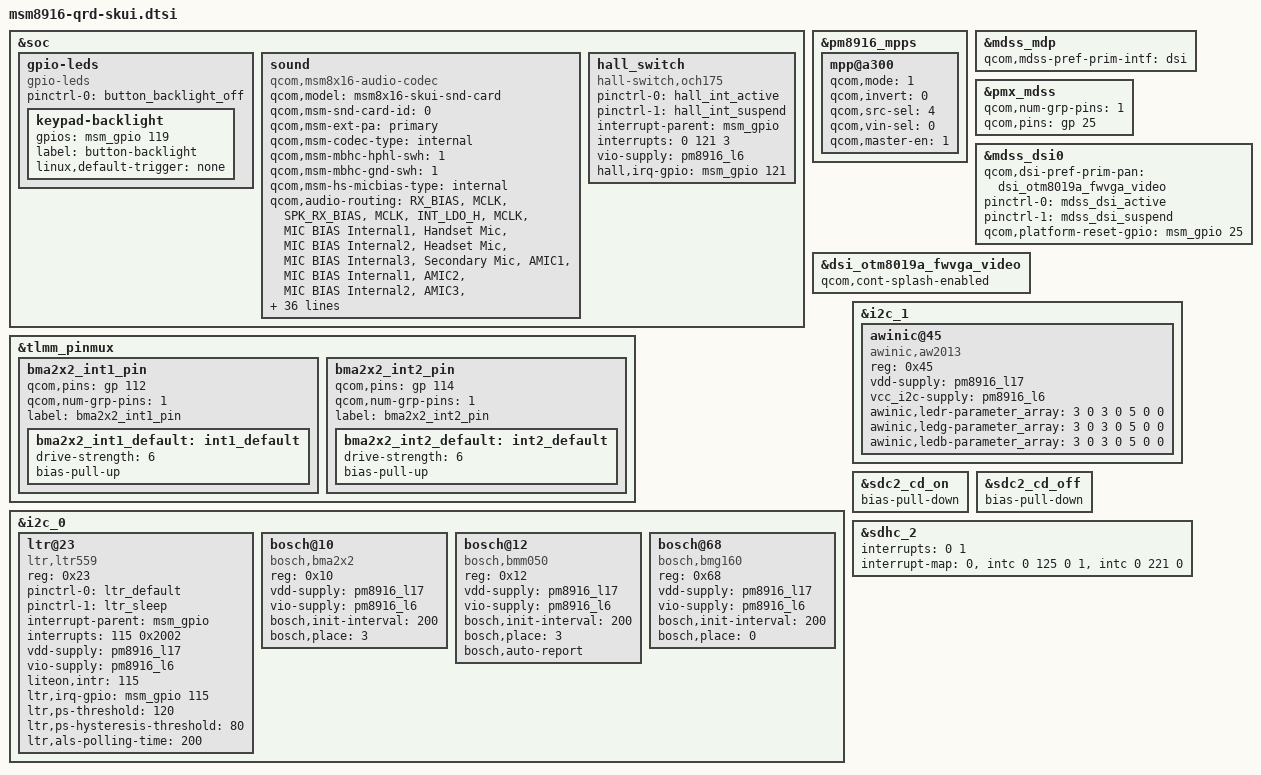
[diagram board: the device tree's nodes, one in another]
/* Copyright (c) 2014, The Linux Foundation. All rights reserved.
 *
 * This program is free software; you can redistribute it and/or modify
 * it under the terms of the GNU General Public License version 2 and
 * only version 2 as published by the Free Software Foundation.
 *
 * This program is distributed in the hope that it will be useful,
 * but WITHOUT ANY WARRANTY; without even the implied warranty of
 * MERCHANTABILITY or FITNESS FOR A PARTICULAR PURPOSE.  See the
 * GNU General Public License for more details.
 */

#include "msm8916-qrd.dtsi"
#include "dsi-panel-otm8019a-fwvga-video.dtsi"
#include "msm8916-camera-sensor-qrd-skui.dtsi"
#include "dsi-panel-dijingILI9881C-720p-video.dtsi"
#include "dsi-panel-booyiOTM1287-720p-video.dtsi"

&soc {
	gpio-leds {
		compatible = "gpio-leds";
		status = "okay";
		pinctrl-names = "default";
		pinctrl-0 = <&button_backlight_off>;

		keypad-backlight {
			gpios = <&msm_gpio 119 0>;
			label = "button-backlight";
			linux,default-trigger = "none";
		};
	};

	sound {
		compatible = "qcom,msm8x16-audio-codec";
		qcom,model = "msm8x16-skui-snd-card";
		qcom,msm-snd-card-id = <0>;
		qcom,msm-ext-pa = "primary";
		qcom,msm-codec-type = "internal";
		qcom,msm-mbhc-hphl-swh = <1>;
		qcom,msm-mbhc-gnd-swh = <1>;
		qcom,msm-hs-micbias-type = "internal";
		qcom,audio-routing =
			"RX_BIAS", "MCLK",
			"SPK_RX_BIAS", "MCLK",
			"INT_LDO_H", "MCLK",
			"MIC BIAS Internal1", "Handset Mic",
			"MIC BIAS Internal2", "Headset Mic",
			"MIC BIAS Internal3", "Secondary Mic",
			"AMIC1", "MIC BIAS Internal1",
			"AMIC2", "MIC BIAS Internal2",
			"AMIC3", "MIC BIAS Internal3";
		pinctrl-names = "cdc_lines_act",
				"cdc_lines_sus";
		pinctrl-0 = <&cdc_pdm_lines_act>;
		pinctrl-1 = <&cdc_pdm_lines_sus>;
		asoc-platform = <&pcm0>, <&pcm1>, <&voip>, <&voice>,
				<&loopback>, <&compress>, <&hostless>,
				<&afe>, <&lsm>, <&routing>, <&lpa>;
		asoc-platform-names = "msm-pcm-dsp.0", "msm-pcm-dsp.1",
				"msm-voip-dsp", "msm-pcm-voice", "msm-pcm-loopback",
				"msm-compress-dsp", "msm-pcm-hostless", "msm-pcm-afe",
				"msm-lsm-client", "msm-pcm-routing", "msm-pcm-lpa";
		asoc-cpu = <&dai_pri_auxpcm>, <&dai_hdmi>,
				<&dai_mi2s0>, <&dai_mi2s1>, <&dai_mi2s2>, <&dai_mi2s3>,
				<&sb_0_rx>, <&sb_0_tx>, <&sb_1_rx>, <&sb_1_tx>,
				<&sb_3_rx>, <&sb_3_tx>, <&sb_4_rx>, <&sb_4_tx>,
				<&bt_sco_rx>, <&bt_sco_tx>, <&int_fm_rx>, <&int_fm_tx>,
				<&afe_pcm_rx>, <&afe_pcm_tx>, <&afe_proxy_rx>, <&afe_proxy_tx>,
				<&incall_record_rx>, <&incall_record_tx>, <&incall_music_rx>,
				<&incall_music_2_rx>;
		asoc-cpu-names = "msm-dai-q6-auxpcm.1", "msm-dai-q6-hdmi.8",
				"msm-dai-q6-mi2s.0", "msm-dai-q6-mi2s.1",
				"msm-dai-q6-mi2s.2", "msm-dai-q6-mi2s.3",
				"msm-dai-q6-dev.16384", "msm-dai-q6-dev.16385",
				"msm-dai-q6-dev.16386", "msm-dai-q6-dev.16387",
				"msm-dai-q6-dev.16390", "msm-dai-q6-dev.16391",
				"msm-dai-q6-dev.16392", "msm-dai-q6-dev.16393",
				"msm-dai-q6-dev.12288", "msm-dai-q6-dev.12289",
				"msm-dai-q6-dev.12292", "msm-dai-q6-dev.12293",
				"msm-dai-q6-dev.224", "msm-dai-q6-dev.225",
				"msm-dai-q6-dev.241", "msm-dai-q6-dev.240",
				"msm-dai-q6-dev.32771", "msm-dai-q6-dev.32772",
				"msm-dai-q6-dev.32773", "msm-dai-q6-dev.32770";
		asoc-codec = <&stub_codec>, <&pm8916_tombak_dig>;
		asoc-codec-names = "msm-stub-codec.1", "tombak_codec";
	};

	//Add hall switch
	hall_switch {
		compatible = "hall-switch,och175";
		pinctrl-names = "hall_active","hall_suspend";
		pinctrl-0 = <&hall_int_active>;
		pinctrl-1 = <&hall_int_suspend>;
		interrupt-parent = <&msm_gpio>;
		interrupts = <0 121 3>;
		vio-supply = <&pm8916_l6>;
		interrupt-names = "hall_irq";
		hall,irq-gpio = <&msm_gpio 121 0x00>;
	};
};

&pm8916_mpps {
	mpp@a300 { /* MPP 4 */
		/* Backlight PWM */
		qcom,mode = <1>;		/* Digital output */
		qcom,invert = <0>;		/* Disable invert */
		qcom,src-sel = <4>;		/* DTEST1 */
		qcom,vin-sel = <0>;		/* VPH_PWR */
		qcom,master-en = <1>;		/* Enable MPP */
	};
};

&mdss_mdp {
	qcom,mdss-pref-prim-intf = "dsi";
};

&pmx_mdss {
	qcom,num-grp-pins = <1>;
	qcom,pins = <&gp 25>;
};

&mdss_dsi0 {
	qcom,dsi-pref-prim-pan = <&dsi_otm8019a_fwvga_video>;
	pinctrl-names = "mdss_default", "mdss_sleep";
	pinctrl-0 = <&mdss_dsi_active>;
	pinctrl-1 = <&mdss_dsi_suspend>;

	qcom,platform-reset-gpio = <&msm_gpio 25 0>;
};

&dsi_otm8019a_fwvga_video {
       qcom,cont-splash-enabled;
};

&tlmm_pinmux {
	bma2x2_int1_pin {
		qcom,pins = <&gp 112>;
		qcom,num-grp-pins = <1>;
		label = "bma2x2_int1_pin";
		bma2x2_int1_default: int1_default {
			  drive-strength = <6>;
			  bias-pull-up;
		};
	};

	bma2x2_int2_pin {
		qcom,pins = <&gp 114>;
		qcom,num-grp-pins = <1>;
		label = "bma2x2_int2_pin";
		bma2x2_int2_default: int2_default {
			  drive-strength = <6>;
			  bias-pull-up;
		};
	};
};

&i2c_0 { /* BLSP1 QUP2 */
	ltr@23 { /* Ambient light and proximity sensor */
		compatible = "ltr,ltr559";
		reg = <0x23>;
		pinctrl-names = "default","sleep";
		pinctrl-0 = <&ltr_default>;
		pinctrl-1 = <&ltr_sleep>;
		interrupt-parent = <&msm_gpio>;
		interrupts = <115 0x2002>;
		vdd-supply = <&pm8916_l17>;
		vio-supply = <&pm8916_l6>;
		liteon,intr = <115>;
		ltr,irq-gpio = <&msm_gpio 115 0x2002>;
		ltr,ps-threshold = <120>;
		ltr,ps-hysteresis-threshold = <80>;
		ltr,als-polling-time = <200>;
	};

	bosch@10 { /* accelerometer sensor */
		compatible = "bosch,bma2x2";
		reg = <0x10>;
		vdd-supply = <&pm8916_l17>;
		vio-supply = <&pm8916_l6>;
		bosch,init-interval = <200>;
		bosch,place = <3>;
	};
	bosch@12 {/* magnetic sensor */
		compatible = "bosch,bmm050";
		reg = <0x12>;
		vdd-supply = <&pm8916_l17>;
		vio-supply = <&pm8916_l6>;
		bosch,init-interval = <200>;
		bosch,place = <3>;
		bosch,auto-report;
	};
	bosch@68 { /* gyroscope sensor */
		compatible = "bosch,bmg160";
		reg = <0x68>;
		vdd-supply = <&pm8916_l17>;
		vio-supply = <&pm8916_l6>;
		bosch,init-interval = <200>;
		bosch,place = <0>;
	};
};

&i2c_1 { /* BLSP1 QUP1 */
		awinic@45 { /* Breath Light-Driven */
			/*
			led_Imax				current;         //0=omA, 1=5mA, 2=10mA, 3=15mA,
			unsigned int			rise_time;      //0=0.13s, 1=0.26s, 2=0.52s, 3=1.04s, 4=2.08s, 5=4.16s, 6=8.32s, 7=16.64s
			unsigned int			hold_time;     //0=0.13s, 1=0.26s, 2=0.52s, 3=1.04s, 4=2.08s, 5=4.16s,
			unsigned int			fall_time;       //0=0.13s, 1=0.26s, 2=0.52s, 3=1.04s, 4=2.08s, 5=4.16s, 6=8.32s, 7=16.64s
			unsigned int			off_time;       //0=0.13s, 1=0.26s, 2=0.52s, 3=1.04s, 4=2.08s, 5=4.16s, 6=8.32s, 7=16.64s
			unsigned int			delay_time;   //0=0.0s, 1=0.13s, 2=0.26s, 3=0.52s, 4=1.04s, 5=2.08s, 6=4.16s, 7=8.32s, 8=16.64s
			unsigned int			period_num; //0=unlimited, 1, 2, 3, 4, ......, 15
			*/
			compatible = "awinic,aw2013";
			reg = <0x45>;
			vdd-supply = <&pm8916_l17>;
			vcc_i2c-supply = <&pm8916_l6>;
			awinic,ledr-parameter_array = <3 0 3 0 5 0 0>;
			awinic,ledg-parameter_array = <3 0 3 0 5 0 0>;
			awinic,ledb-parameter_array = <3 0 3 0 5 0 0>;
		};
};


&sdc2_cd_on {
	/delete-property/ bias-pull-up;
	bias-pull-down;
};

&sdc2_cd_off {
	/delete-property/ bias-disable;
	bias-pull-down;
};

&sdhc_2 {
	interrupts = <0 1>;
	interrupt-map = <0 &intc 0 125 0
		1 &intc 0 221 0>;
	interrupt-names = "hc_irq", "pwr_irq";
	/delete-property/ cd-gpios;
};

